# STM32N645xx register map
File version: 1.0
Registers are 32-bit, read-write, reset 0x0 unless marked. A register's access mark holds for its fields unless they carry their own. Offsets are from the block's base; [hi:lo] are bit positions; 'fields as' and 'values as' point back to an identical list.

## RAMCFG — RAMs configuration controller
Base 0x42023000
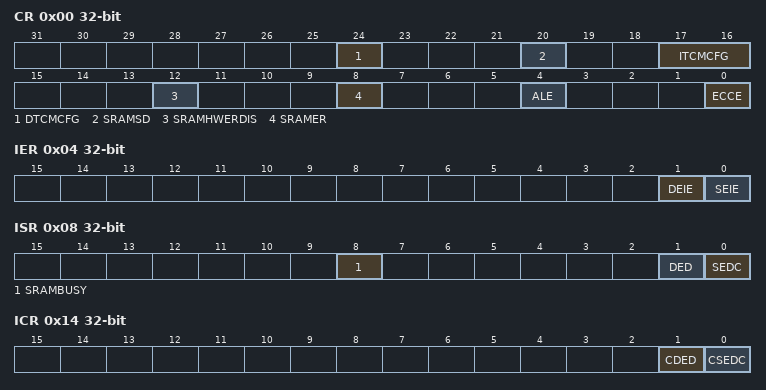
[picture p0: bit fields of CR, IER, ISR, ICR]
0x00 CR — Control Register
  [24] DTCMCFG — Configuration of the FLEXMEM D-TCM extension
  [20] SRAMSD — Shutdown AXISRAMx
  [17:16] ITCMCFG — Configuration of the FLEXMEM D-TCM extension
  [12] SRAMHWERDIS — SRAM hardware erase disable
  [8] SRAMER — Start Erase
  [4] ALE — Address Latching Enable
  [0] ECCE — ECC Enable
0x04 IER — Interrupt Enable Register
  [1] DEIE — Double Error Interrupt Enable
  [0] SEIE — Single Error Interrupt Enable
0x08 ISR — Interrupt Status Register
  [8] SRAMBUSY — SRAM busy flag
  [1] DED — Double Error Detected flag
  [0] SEDC — Single Error Detected and Corrected flag
0x0C ESEAR — ECC Single Error Address Register
  [10:0] ESEA — ECC Single Error Address
0x10 EDEAR — ECC Double Error Address Register
  [10:0] EDEA — ECC Double Error Address
0x14 ICR — Interrupt Clear Register
  [1] CDED — Clear ECC Double Error Detected Flag
  [0] CSEDC — Clear ECC Single Error Detected and Corrected Flag
0x24 ECCKEYR — RAM ECC Key Register
  [7:0] ECCKEY — ECC Write Protection Key
0x28 ERKEYR — RAM Erase Key Register
  [7:0] ERASEKEY — Erase Write Protection Key
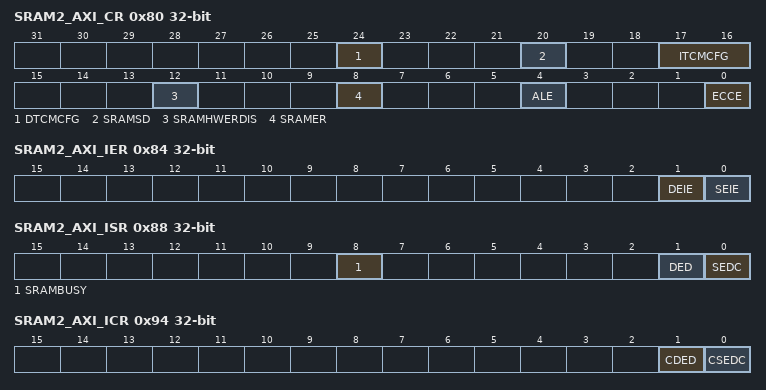
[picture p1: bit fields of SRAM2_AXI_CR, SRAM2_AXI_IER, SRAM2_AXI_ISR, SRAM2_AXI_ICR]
0x80 SRAM2_AXI_CR — Control Register
  fields as CR
0x84 SRAM2_AXI_IER — Interrupt Enable Register
  fields as IER
0x88 SRAM2_AXI_ISR — Interrupt Status Register
  fields as ISR
0x8C SRAM2_AXI_ESEAR — ECC Single Error Address Register
  [10:0] ESEA — ECC Single Error Address
0x90 SRAM2_AXI_EDEAR — ECC Double Error Address Register
  [10:0] EDEA — ECC Double Error Address
0x94 SRAM2_AXI_ICR — Interrupt Clear Register
  fields as ICR
0xA4 SRAM2_AXI_ECCKEYR — RAM ECC Key Register
  [7:0] ECCKEY — ECC Write Protection Key
0xA8 SRAM2_AXI_ERKEYR — RAM Erase Key Register
  [7:0] ERASEKEY — Erase Write Protection Key
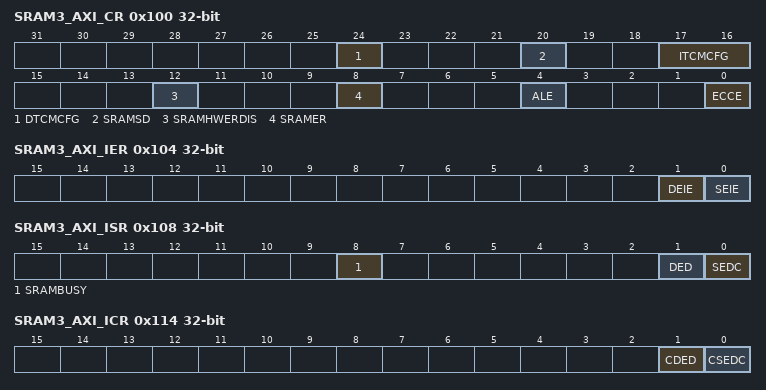
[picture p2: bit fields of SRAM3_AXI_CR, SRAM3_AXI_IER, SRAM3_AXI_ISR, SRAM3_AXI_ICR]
0x100 SRAM3_AXI_CR — Control Register
  fields as CR
0x104 SRAM3_AXI_IER — Interrupt Enable Register
  fields as IER
0x108 SRAM3_AXI_ISR — Interrupt Status Register
  fields as ISR
0x10C SRAM3_AXI_ESEAR — ECC Single Error Address Register
  [10:0] ESEA — ECC Single Error Address
0x110 SRAM3_AXI_EDEAR — ECC Double Error Address Register
  [10:0] EDEA — ECC Double Error Address
0x114 SRAM3_AXI_ICR — Interrupt Clear Register
  fields as ICR
0x124 SRAM3_AXI_ECCKEYR — RAM ECC Key Register
  [7:0] ECCKEY — ECC Write Protection Key
0x128 SRAM3_AXI_ERKEYR — RAM Erase Key Register
  [7:0] ERASEKEY — Erase Write Protection Key
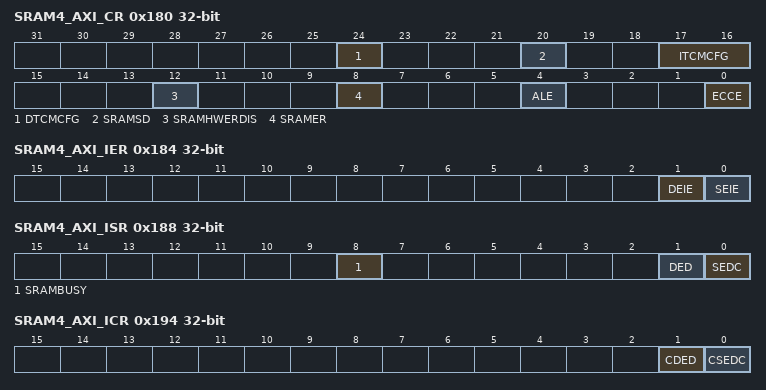
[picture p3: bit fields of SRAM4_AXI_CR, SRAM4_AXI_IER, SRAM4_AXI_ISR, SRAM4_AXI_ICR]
0x180 SRAM4_AXI_CR — Control Register
  fields as CR
0x184 SRAM4_AXI_IER — Interrupt Enable Register
  fields as IER
0x188 SRAM4_AXI_ISR — Interrupt Status Register
  fields as ISR
0x18C SRAM4_AXI_ESEAR — ECC Single Error Address Register
  [10:0] ESEA — ECC Single Error Address
0x190 SRAM4_AXI_EDEAR — ECC Double Error Address Register
  [10:0] EDEA — ECC Double Error Address
0x194 SRAM4_AXI_ICR — Interrupt Clear Register
  fields as ICR
0x1A4 SRAM4_AXI_ECCKEYR — RAM ECC Key Register
  [7:0] ECCKEY — ECC Write Protection Key
0x1A8 SRAM4_AXI_ERKEYR — RAM Erase Key Register
  [7:0] ERASEKEY — Erase Write Protection Key
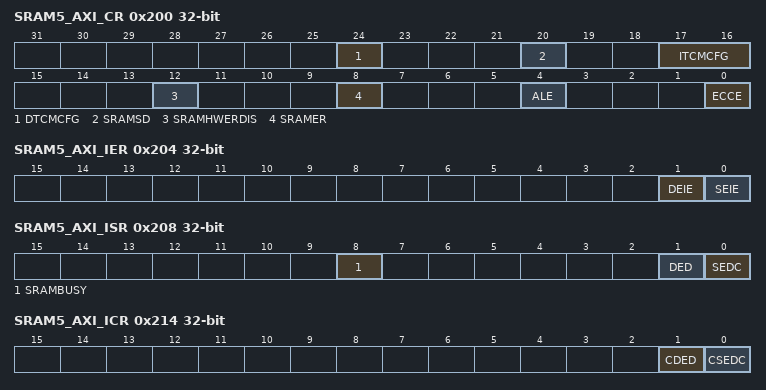
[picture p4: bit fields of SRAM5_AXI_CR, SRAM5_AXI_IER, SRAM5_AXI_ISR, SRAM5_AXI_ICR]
0x200 SRAM5_AXI_CR — Control Register
  fields as CR
0x204 SRAM5_AXI_IER — Interrupt Enable Register
  fields as IER
0x208 SRAM5_AXI_ISR — Interrupt Status Register
  fields as ISR
0x20C SRAM5_AXI_ESEAR — ECC Single Error Address Register
  [10:0] ESEA — ECC Single Error Address
0x210 SRAM5_AXI_EDEAR — ECC Double Error Address Register
  [10:0] EDEA — ECC Double Error Address
0x214 SRAM5_AXI_ICR — Interrupt Clear Register
  fields as ICR
0x224 SRAM5_AXI_ECCKEYR — RAM ECC Key Register
  [7:0] ECCKEY — ECC Write Protection Key
0x228 SRAM5_AXI_ERKEYR — RAM Erase Key Register
  [7:0] ERASEKEY — Erase Write Protection Key
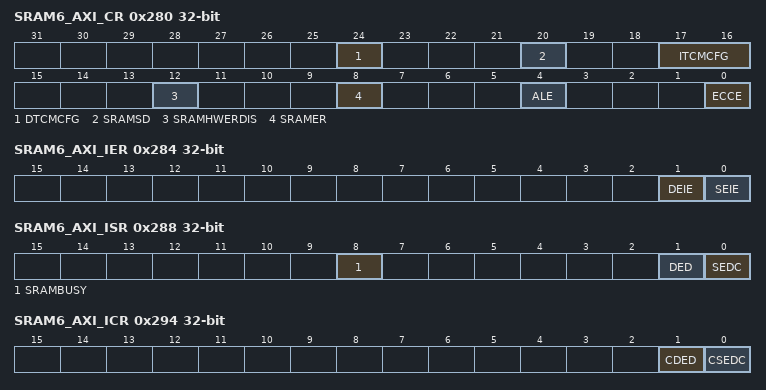
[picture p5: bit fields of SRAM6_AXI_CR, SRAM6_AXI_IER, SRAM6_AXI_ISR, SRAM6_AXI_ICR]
0x280 SRAM6_AXI_CR — Control Register
  fields as CR
0x284 SRAM6_AXI_IER — Interrupt Enable Register
  fields as IER
0x288 SRAM6_AXI_ISR — Interrupt Status Register
  fields as ISR
0x28C SRAM6_AXI_ESEAR — ECC Single Error Address Register
  [10:0] ESEA — ECC Single Error Address
0x290 SRAM6_AXI_EDEAR — ECC Double Error Address Register
  [10:0] EDEA — ECC Double Error Address
0x294 SRAM6_AXI_ICR — Interrupt Clear Register
  fields as ICR
0x2A4 SRAM6_AXI_ECCKEYR — RAM ECC Key Register
  [7:0] ECCKEY — ECC Write Protection Key
0x2A8 SRAM6_AXI_ERKEYR — RAM Erase Key Register
  [7:0] ERASEKEY — Erase Write Protection Key
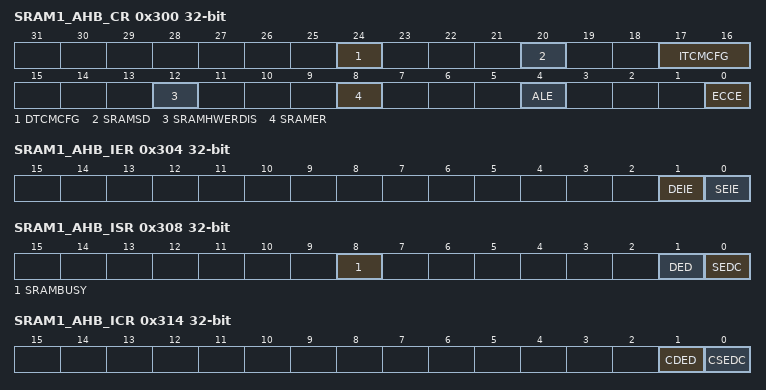
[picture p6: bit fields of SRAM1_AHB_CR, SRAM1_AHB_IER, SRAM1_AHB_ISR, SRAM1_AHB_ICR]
0x300 SRAM1_AHB_CR — Control Register
  fields as CR
0x304 SRAM1_AHB_IER — Interrupt Enable Register
  fields as IER
0x308 SRAM1_AHB_ISR — Interrupt Status Register
  fields as ISR
0x30C SRAM1_AHB_ESEAR — ECC Single Error Address Register
  [10:0] ESEA — ECC Single Error Address
0x310 SRAM1_AHB_EDEAR — ECC Double Error Address Register
  [10:0] EDEA — ECC Double Error Address
0x314 SRAM1_AHB_ICR — Interrupt Clear Register
  fields as ICR
0x324 SRAM1_AHB_ECCKEYR — RAM ECC Key Register
  [7:0] ECCKEY — ECC Write Protection Key
0x328 SRAM1_AHB_ERKEYR — RAM Erase Key Register
  [7:0] ERASEKEY — Erase Write Protection Key
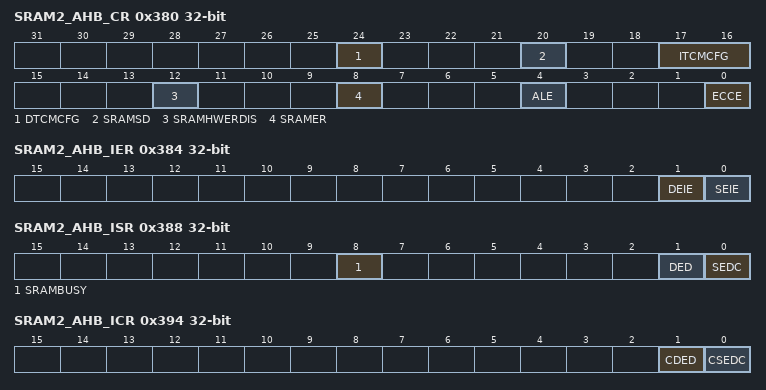
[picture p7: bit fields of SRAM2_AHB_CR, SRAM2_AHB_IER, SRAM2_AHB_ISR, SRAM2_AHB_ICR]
0x380 SRAM2_AHB_CR — Control Register
  fields as CR
0x384 SRAM2_AHB_IER — Interrupt Enable Register
  fields as IER
0x388 SRAM2_AHB_ISR — Interrupt Status Register
  fields as ISR
0x38C SRAM2_AHB_ESEAR — ECC Single Error Address Register
  [10:0] ESEA — ECC Single Error Address
0x390 SRAM2_AHB_EDEAR — ECC Double Error Address Register
  [10:0] EDEA — ECC Double Error Address
0x394 SRAM2_AHB_ICR — Interrupt Clear Register
  fields as ICR
0x3A4 SRAM2_AHB_ECCKEYR — RAM ECC Key Register
  [7:0] ECCKEY — ECC Write Protection Key
0x3A8 SRAM2_AHB_ERKEYR — RAM Erase Key Register
  [7:0] ERASEKEY — Erase Write Protection Key
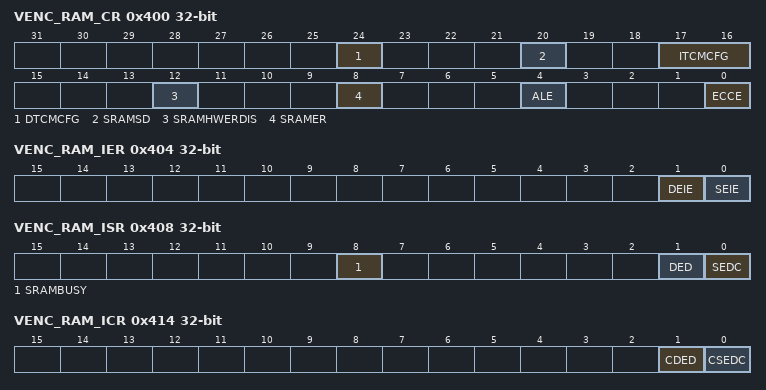
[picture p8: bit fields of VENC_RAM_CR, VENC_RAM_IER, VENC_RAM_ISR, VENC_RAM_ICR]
0x400 VENC_RAM_CR — Control Register
  fields as CR
0x404 VENC_RAM_IER — Interrupt Enable Register
  fields as IER
0x408 VENC_RAM_ISR — Interrupt Status Register
  fields as ISR
0x40C VENC_RAM_ESEAR — ECC Single Error Address Register
  [10:0] ESEA — ECC Single Error Address
0x410 VENC_RAM_EDEAR — ECC Double Error Address Register
  [10:0] EDEA — ECC Double Error Address
0x414 VENC_RAM_ICR — Interrupt Clear Register
  fields as ICR
0x424 VENC_RAM_ECCKEYR — RAM ECC Key Register
  [7:0] ECCKEY — ECC Write Protection Key
0x428 VENC_RAM_ERKEYR — RAM Erase Key Register
  [7:0] ERASEKEY — Erase Write Protection Key
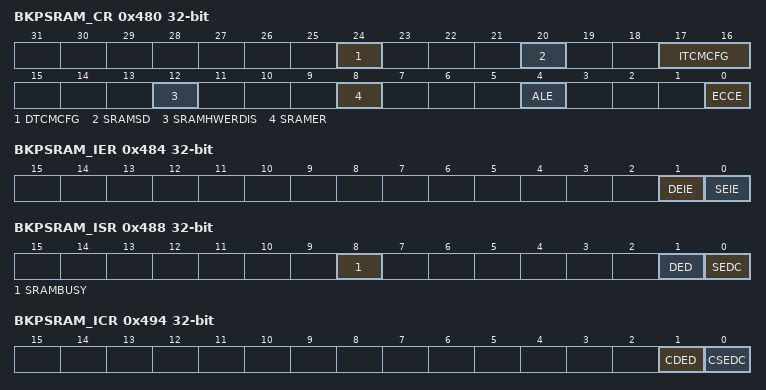
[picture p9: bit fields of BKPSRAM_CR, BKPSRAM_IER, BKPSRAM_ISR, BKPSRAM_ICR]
0x480 BKPSRAM_CR — Control Register
  fields as CR
0x484 BKPSRAM_IER — Interrupt Enable Register
  fields as IER
0x488 BKPSRAM_ISR — Interrupt Status Register
  fields as ISR
0x48C BKPSRAM_ESEAR — ECC Single Error Address Register
  [10:0] ESEA — ECC Single Error Address
0x490 BKPSRAM_EDEAR — ECC Double Error Address Register
  [10:0] EDEA — ECC Double Error Address
0x494 BKPSRAM_ICR — Interrupt Clear Register
  fields as ICR
0x4A4 BKPSRAM_ECCKEYR — RAM ECC Key Register
  [7:0] ECCKEY — ECC Write Protection Key
0x4A8 BKPSRAM_ERKEYR — RAM Erase Key Register
  [7:0] ERASEKEY — Erase Write Protection Key
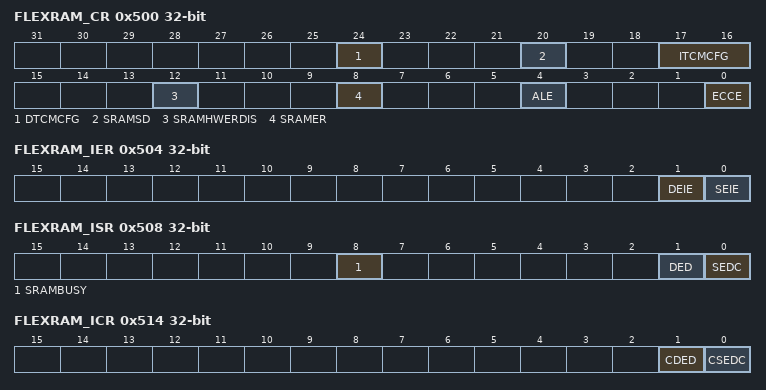
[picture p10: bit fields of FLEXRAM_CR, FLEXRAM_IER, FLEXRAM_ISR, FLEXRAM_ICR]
0x500 FLEXRAM_CR — Control Register
  fields as CR
0x504 FLEXRAM_IER — Interrupt Enable Register
  fields as IER
0x508 FLEXRAM_ISR — Interrupt Status Register
  fields as ISR
0x50C FLEXRAM_ESEAR — ECC Single Error Address Register
  [10:0] ESEA — ECC Single Error Address
0x510 FLEXRAM_EDEAR — ECC Double Error Address Register
  [10:0] EDEA — ECC Double Error Address
0x514 FLEXRAM_ICR — Interrupt Clear Register
  fields as ICR
0x524 FLEXRAM_ECCKEYR — RAM ECC Key Register
  [7:0] ECCKEY — ECC Write Protection Key
0x528 FLEXRAM_ERKEYR — RAM Erase Key Register
  [7:0] ERASEKEY — Erase Write Protection Key
